# nrf9120_MLM1 register map
Vendor: Nordic Semiconductor; Series: nrf91; File version: 1
CPU: CM4 r0p1, little endian, MPU, FPU, 3 interrupt priority bits
Registers are 32-bit, read-write, reset 0x0 unless marked. A register's access mark holds for its fields unless they carry their own. Offsets are from the block's base; [hi:lo] are bit positions; lines under a group give offsets from that group; {n}, {i} and the like mark numbered series.

## NVMC — Non Volatile Memory Controller
Base 0x40030000
0x400 READY ro — Ready flag
  [0] READY — NVMC is ready or busy
    0=Busy (NVMC is busy (on-going write or erase operation)); 1=Ready (NVMC is ready)
0x404 VERIFYFAILED ro — Flag to signal that a flash erase or write operation has failed
  [0] FAILED — Indicates if an erase or write operation has failed. This bit will then remain set until next reset, even if successful writes or erases occur after a failing one.
    0=OK (No erase or write operation has failed since last reset); 1=Failed (At least one erase or write operation has failed)
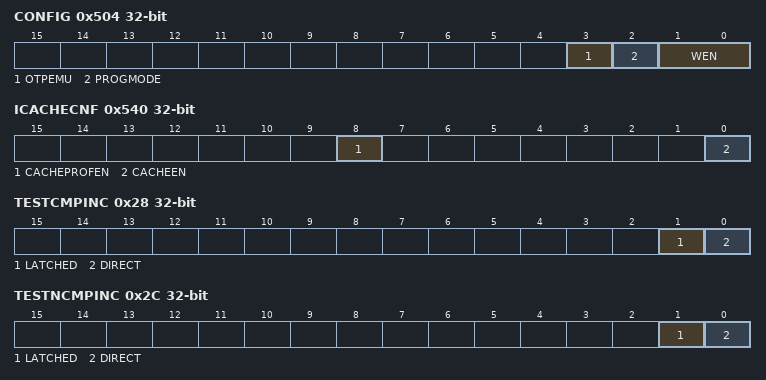
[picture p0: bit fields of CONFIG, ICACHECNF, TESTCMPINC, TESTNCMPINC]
0x504 CONFIG — Configuration register
  [3] OTPEMU — Deprecated field - OTP Emulation mode
    0=Disabled (OTP Emulation disabled); 1=Enabled (OTP Emulation enabled)
  [2] PROGMODE — Deprecated field - Halt CPU until current write or erase command is finished
    0=Halt CPU; 1=NoHalt (Do not halt CPU)
  [1:0] WEN — Program memory access mode. It is strongly recommended to only activate erase and write modes when they are actively used. Enabling write or erase will invalidate the cache and keep it invalidated.
    0=Ren (Read only access); 1=Wen (Write Enabled); 2=Een (Erase enabled)
0x508 ERASEPAGE — Register for erasing a page in Code area
  [31:0] ERASEPAGE — Register for starting erase of a page in Code area
0x508 ERASEPCR1 (alternate view of ERASEPAGE) — Deprecated register - Register for erasing a page in Code area. Equivalent to ERASEPAGE.
  [31:0] ERASEPCR1 — Register for erasing a page in Code area. Equivalent to ERASEPAGE.
0x50C ERASEALL — Register for erasing all non-volatile user memory
  [0] ERASEALL — Erase all non-volatile memory including UICR registers. Note that the erase must be enabled using CONFIG.WEN before the non-volatile memory can be erased.
    0=NoOperation; 1=Erase (Start chip erase)
0x510 ERASEPCR0 — Deprecated register - Register for erasing a page in Code area. Equivalent to ERASEPAGE.
  [31:0] ERASEPCR0 — Register for starting erase of a page in Code area. Equivalent to ERASEPAGE.
0x514 ERASEUICR — Register for erasing User Information Configuration Registers
  [0] ERASEUICR — Register starting erase of all User Information Configuration Registers. Note that the erase must be enabled using CONFIG.WEN before the UICR can be erased.
    0=NoOperation; 1=Erase (Start erase of UICR)
0x518 ERASEPAGEPARTIAL — Register for partial erase of a page in Code area
  [31:0] ERASEPAGEPARTIAL — Register for starting partial erase of a page in Code area
0x51C ERASEPAGEPARTIALCFG reset 0xA — Register for partial erase configuration
  [6:0] DURATION — Duration of the partial erase in milliseconds
0x530 WAITSTATENUM reset 0xF — Register to set the number of waitstate for flash access
  [3:0] WAITSTATENUM — Register to set the number of waitstate for the flash acces
0x540 ICACHECNF — I-Code cache configuration register.
  [8] CACHEPROFEN — Cache profiling enable
    0=Disabled (Disable cache profiling); 1=Enabled (Enable cache profiling)
  [0] CACHEEN — Cache enable
    0=Disabled (Disable cache. Invalidates all cache entries.); 1=Enabled (Enable cache)
0x548 IHIT — I-Code cache hit counter.
  [31:0] HITS — Number of cache hits
0x54C IMISS — I-Code cache miss counter.
  [31:0] MISSES — Number of cache misses
0x600 TESTMODE — Register for entering test mode. Refer to the flash IP test documentation for more details.
  [15:0] TESTMODE — Register for entering test mode. Refer to the flash IP test documentation for more details. This register does not return the same value as written.
    on read: 0=NORMAL (Read: Not in test-mode.); 1=Read: In test-mode 1; 2=Read: In test-mode 2; 4=Read: In test-mode 3 | on write: 0=SetNORMAL (Write: Sets NORMAL mode.); 0xBCDE=SetTESTMODE1 (Write: Sets test-mode 1.); 0xABCD=SetTESTMODE2 (Write: Sets test-mode 2.); 0xCDEF=SetTESTMODE3 (Write: Sets test-mode 3.)
0x604 LVEN — Low Voltage Read Mode
0x608 UNUSED0 — Unspecified
0x60C UNUSED1 — Unspecified
0x610 TESTMASSERASE wo — Self-timed mass-erase operation
  [1:0] TESTMASSERASE
    3=EVERYTHING (Erase everything (all information pages and main block)); 2=MAIN (Erase only the main block); 1=NOOPERATION1; 0=NOOPERATION0
0x614 TESTERASEREFCELL wo — Self-timed erase reference cell operation
  [0] TESTERASEREFCELL
    1=START (Start the erase reference cell operation); 0=NOOPERATION
0x618 TEST group — Unspecified
  0x00 TESTTC ro — Description cluster[0]: Observe the TC output from the flash macro
    [12:0] TC — TC output
  0x04 UNUSED0 — Unspecified
  {0x8+4j} TESTDATA128[{j}] (j=0..3) — Description collection[0]: Direct flash test data word 0
    [31:0] TESTDATA — Returns data out from flash when reading. Sets flash data in when writing.
  {0x18+4j} TESTDATA128INC[{j}] (j=0..3) ro — Description collection[0]: Direct flash test data word 0. Post-increments TESTCONTROLADDR
    [31:0] TESTDATA — Returns data out from flash when reading. Use TESTDATA128[3:0] registers to set the compared data. Post-increments TESTCONTROLADDR. If TESTCONTROLLINES.SE is high, the read starts by pulsing the SE line low for Tnws. If TESTCONTROLLINES.SE is low, SE remains low for the whole access.
  0x28 TESTCMPINC ro — Description cluster[0]: Reads and compares last flash row to TESTDATA128 content. Post-increments TESTCONTROLADDR.
    [1] LATCHED — Reads and compares last flash row (latched lines) to TESTDATA128 content. Post-increments TESTCONTROLADDR. If TESTCONTROLLINES.SE is high, the read starts by pulsing the SE line low for Tnws. If TESTCONTROLLINES.SE is low, SE remains low for the whole access.
      0=Equal (Latched TESTDATA128 content and flash row read are equal); 1=NotEqual (Latched TESTDATA128 content and flash row read are different)
    [0] DIRECT — Reads and compares last flash row (direct lines) to TESTDATA128 content. Post-increments TESTCONTROLADDR. If TESTCONTROLLINES.SE is high, the read starts by pulsing the SE line low for Tnws. If TESTCONTROLLINES.SE is low, SE remains low for the whole access.
      0=Equal (Direct TESTDATA128 content and flash row read are equal); 1=NotEqual (Direct TESTDATA128 content and flash row read are different)
  0x2C TESTNCMPINC ro — Description cluster[0]: Reads and compares last flash row to complement of TESTDATA128 content. Post-increments TESTCONTROLADDR.
    [1] LATCHED — Reads and compares last flash row (latched lines) to the complement of TESTDATA128 content (all bits inverted). Post-increments TESTCONTROLADDR. If TESTCONTROLLINES.SE is high, the read starts by pulsing the SE line low for Tnws. If TESTCONTROLLINES.SE is low, SE remains low for the whole access.
      0=Complement (Latched TESTDATA128 content and flash row read are each-other's complement); 1=NotComplement (Latched TESTDATA128 content and flash row read are not each-other's complement)
    [0] DIRECT — Reads and compares last flash row (direct lines) to the complement of TESTDATA128 content (all bits inverted). Post-increments TESTCONTROLADDR. If TESTCONTROLLINES.SE is high, the read starts by pulsing the SE line low for Tnws. If TESTCONTROLLINES.SE is low, SE remains low for the whole access.
      0=Complement (Direct TESTDATA128 content and flash row read are each-other's complement); 1=NotComplement (Direct TESTDATA128 content and flash row read are not each-other's complement)
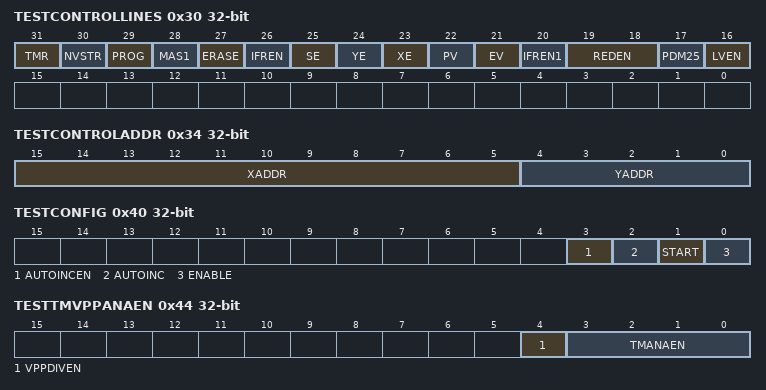
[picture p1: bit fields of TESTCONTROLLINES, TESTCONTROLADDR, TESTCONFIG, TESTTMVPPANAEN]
  0x30 TESTCONTROLLINES — Description cluster[0]: Direct flash test, control lines. Refer to the flash IP test documentation for more details.
    [31] TMR — Control the TMR signal
    [30] NVSTR — Control the NVSTR signal
    [29] PROG — Control the PROG signal
    [28] MAS1 — Control the MAS1 signal
    [27] ERASE — Control the ERASE signal
    [26] IFREN — Control the IFREN signal
    [25] SE — Control the SE signal. This signal is delayed by hardware by Tas, so that it can be written simultaneously to XE and YE
    [24] YE — Control the YE signal
    [23] XE — Control the XE signal
    [22] PV — Control the PV signal
    [21] EV — Control the EV signal
    [20] IFREN1 — Control the IFREN1 signal
    [19:18] REDEN — Control the REDEN signal
    [17] PDM25 — Control the PDM25 signal
    [16] LVEN — Control the LVEN signal
  0x34 TESTCONTROLADDR — Description cluster[0]: Direct flash test control, address lines
    [15:5] XADDR — Control the XADDR signal
    [4:0] YADDR — Control the YADDR signal
  0x38 TESTCOUNTERRELOAD — Description cluster[0]: Counter reload value, used when counting from SE or YE rising edge to latching of data
    [13:0] RELOAD — Counter reload value, in MCU bus cycles, used when counting from SE or YE rising edge to latching of data. Value of 0 has no effect (counter will not latch)
  0x3C TESTCOUNTERRUNNING ro — Description cluster[0]: Returns the state (counting or not) of the counter
    [0] RUNNING — Returns the state of the counter
      0=NotRunning (Counter is not running); 1=Running (Counter is running)
  0x40 TESTCONFIG — Description cluster[0]: Mode of operation of the counter
    [3] AUTOINCEN — Disables the address auto-increment or -decrement
      1=Disable (Address auto-incrementing/decrementing is disabled); 0=Enable (Address auto-incrementing/decrementing is enabled)
    [2] AUTOINC — Controls the address auto-increment or -decrement
      0=Increment (Address is auto-incrementing); 1=Decrement (Address is auto-decrementing)
    [1] START — Defines the starting point of the counter
      0=SE (Counter starts on SE rising edge); 1=YE (Counter starts on YE rising edge)
    [0] ENABLE — Returns the state of the counter
      0=Disabled (Counter is disabled); 1=Enabled (Counter is enabled)
  0x44 TESTTMVPPANAEN — Description cluster[0]: Controls analog signals for flash measurements
    [4] VPPDIVEN — Enable the VPPDIV pad. Needs to be set when measuring VPPDIV on GPIO26 (P0.20), and when applying high-voltage on VPP pad.
      0=Disabled (VPPDIV pad disabled); 1=Enabled (VPPDIV pad enabled)
    [3:0] TMANAEN — Analog enable for TM measurement. Needs to be set when measuring TM[3:0] on P0.05, P0.04, P0.01 and P0.00.
      0=Disabled (All pads disabled); 15=Enabled (All pads enabled)
  {0x48+4j} UNUSED1[{j}] (j=0..13) — Description collection[0]: Unspecified
